# XMC4300 register map
Vendor: Infineon; File version: 0.5.1 (Superset device XMC4800)
CPU: CM4 r2p0, little endian, MPU, FPU, 6 interrupt priority bits
Registers are 32-bit, read-write, reset 0x0 unless marked. A register's access mark holds for its fields unless they carry their own. Offsets are from the block's base; [hi:lo] are bit positions; {n}, {i} and the like mark numbered series; 'fields as' and 'values as' point back to an identical list.

## DAC — Digital to Analog Converter
Base 0x48018000
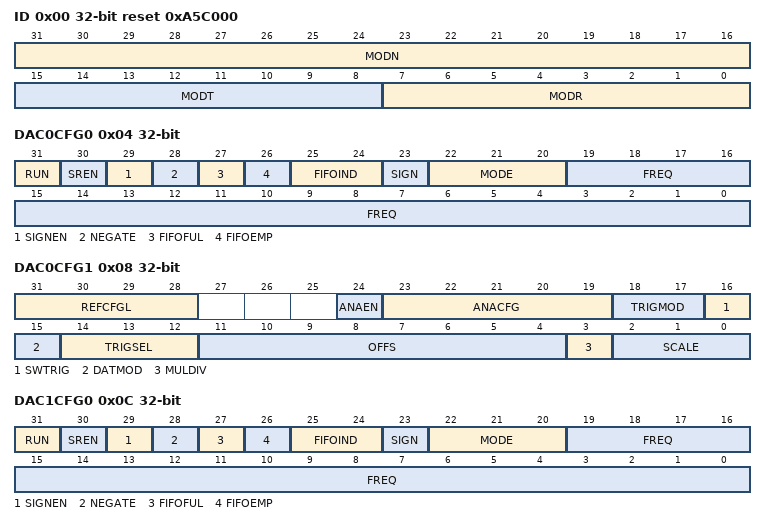
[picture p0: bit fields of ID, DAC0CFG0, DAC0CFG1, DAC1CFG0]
0x00 ID ro reset 0xA5C000 (reset mask 0xFFFFFF00) — Module Identification Register
  [31:16] MODN — Module Number
  [15:8] MODT — Module Type
  [7:0] MODR — Module Revision
0x04 DAC0CFG0 access per field — DAC0 Configuration Register 0
  [31] RUN ro — RUN indicates the current DAC0 operation status
    0=DAC0 channel disabled; 1=DAC0 channel in operation
  [30] SREN rw — Enable DAC0 service request interrupt generation
    0=disable; 1=enable
  [29] SIGNEN rw — Enable Sign Output of DAC0 Pattern Generator
    0=Disable; 1=Enable
  [28] NEGATE rw — Negates the DAC0 output
    0=DAC output not negated; 1=DAC output negated
  [27] FIFOFUL ro — Indicate if the FIFO is full
    0=FIFO not full; 1=FIFO full
  [26] FIFOEMP ro — Indicate if the FIFO is empty
    0=FIFO not empty; 1=FIFO empty
  [25:24] FIFOIND ro — Current write position inside the data FIFO
  [23] SIGN rw — Selects Between Signed and Unsigned DAC0 Mode
    0=DAC expects unsigned input data; 1=DAC expects signed input data
  [22:20] MODE rw — Enables and Sets the Mode for DAC0
    0=disable/switch-off DAC; 1=Single Value Mode; 2=Data Mode; 3=Patgen Mode; 4=Noise Mode; 5=Ramp Mode; 6=na; 7=na
  [19:0] FREQ rw — Integer Frequency Divider Value
0x08 DAC0CFG1 — DAC0 Configuration Register 1
  [31:28] REFCFGL — Lower 4 band-gap configuration/calibration parameters
  [24] ANAEN — Enable analog DAC for channel 0
    0=DAC0 is set to standby (analog output only); 1=enable DAC0 (analog output only)
  [23:19] ANACFG — DAC0 analog configuration/calibration parameters
  [18:17] TRIGMOD — Select the trigger source for channel 0
    0=internal Trigger (integer divided clock - see FREQ parameter); 1=external Trigger (preselected trigger by TRIGSEL parameter); 2=software Trigger (see SWTRIG parameter)
  [16] SWTRIG — Software Trigger
  [15] DATMOD — Switch between independent or simultaneous DAC mode and select the input data register for DAC0 and DAC1
    0=independent data handling - process data from DATA0 register (bits 11:0) to DAC0 and data from DATA1 register (bits 11:0) to DAC1; 1=simultaneous data handling - process data from DAC01 register to both DACs (bits 11:0 to DAC0 and bits 23:12 to DAC1)
  [14:12] TRIGSEL — Selects one of the eight external trigger sources for DAC0
  [11:4] OFFS — 8-bit offset value addition
  [3] MULDIV — Switch between up- and downscale of the DAC0 input data values
    0=downscale = division (shift SCALE positions to the right); 1=upscale = multiplication (shift SCALE positions to the left)
  [2:0] SCALE — Scale value for up- or downscale of the DAC0 input data in steps by the power of 2 (=shift operation)
    0=no shift = multiplication/division by 1; 1=shift by 1 = multiplication/division by 2; 2=shift by 2 = multiplication/division by 4; 3=shift left by 3 = multiplication/division by 8; 4=shift left by 4 = multiplication/division by 16; 5=shift left by 5 = multiplication/division by 32; 6=shift left by 6 = multiplication/division by 64; 7=shift left by 7 = multiplication/division by 128
0x0C DAC1CFG0 access per field — DAC1 Configuration Register 0
  [31] RUN ro — RUN indicates the current DAC1 operation status
    0=DAC1 channel disabled; 1=DAC1 channel in operation
  [30] SREN rw — Enable DAC1 service request interrupt generation
    0=disable; 1=enable
  [29] SIGNEN rw — Enable sign output of DAC1 pattern generator
    0=disable; 1=enable
  [28] NEGATE rw — Negates the DAC1 output
    0=DAC output not negated; 1=DAC output negated
  [27] FIFOFUL ro — Indicate if the FIFO is full
    0=FIFO not full; 1=FIFO full
  [26] FIFOEMP ro — Indicate if the FIFO is empty
    0=FIFO not empty; 1=FIFO empty
  [25:24] FIFOIND ro — Current write position inside the data FIFO
  [23] SIGN rw — Selects between signed and unsigned DAC1 mode
    values as DAC0CFG0.SIGN
  [22:20] MODE rw — Enables and sets the Mode for DAC1
    values as DAC0CFG0.MODE
  [19:0] FREQ rw — Integer Frequency Divider Value
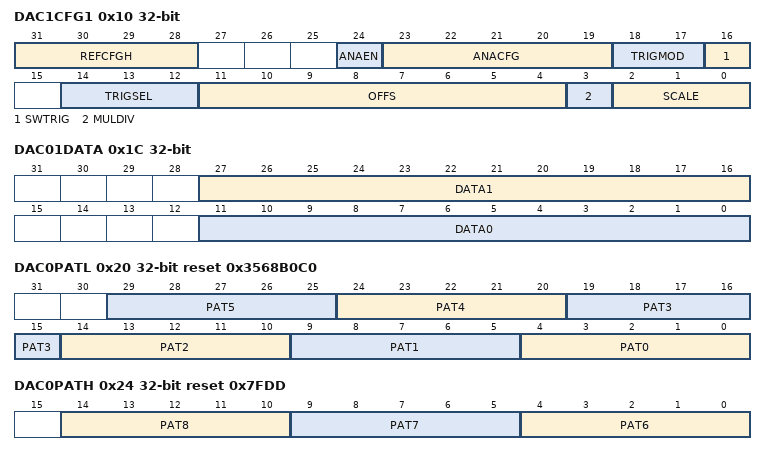
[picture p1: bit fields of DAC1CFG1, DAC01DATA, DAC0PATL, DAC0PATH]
0x10 DAC1CFG1 — DAC1 Configuration Register 1
  [31:28] REFCFGH — Higher 4 band-gap configuration/calibration parameters
  [24] ANAEN — Enable analog DAC for channel 1
    0=DAC1 is set to standby (analog output only); 1=enable DAC1 (analog output only)
  [23:19] ANACFG — DAC1 analog configuration/calibration parameters
  [18:17] TRIGMOD — Select the trigger source for channel 1
    values as DAC0CFG1.TRIGMOD
  [16] SWTRIG — Software Trigger
  [14:12] TRIGSEL — Selects one of the eight external trigger sources for DAC1
  [11:4] OFFS — 8-bit offset value addition
  [3] MULDIV — Switch between up- and downscale of the DAC1 input data values
    values as DAC0CFG1.MULDIV
  [2:0] SCALE — Scale value for up- or downscale of the DAC1 input data in steps by the power of 2 (=shift operation)
    values as DAC0CFG1.SCALE
0x14 DAC0DATA
  [11:0] DATA0 — DAC0 Data Bits
0x18 DAC1DATA
  [11:0] DATA1 — DAC1 Data Bits
0x1C DAC01DATA
  [27:16] DATA1 — DAC1 Data Bits
  [11:0] DATA0 — DAC0 Data Bits
0x20 DAC0PATL reset 0x3568B0C0 — DAC0 Lower Pattern Register
  [5n+4:5n] PAT{n} (n=0..5) — Pattern Number {n} for PATGEN of DAC0
0x24 DAC0PATH reset 0x7FDD — DAC0 Higher Pattern Register
  [14:10] PAT8 — Pattern Number 8 for PATGEN of DAC0
  [9:5] PAT7 — Pattern Number 7 for PATGEN of DAC0
  [4:0] PAT6 — Pattern Number 6 for PATGEN of DAC0
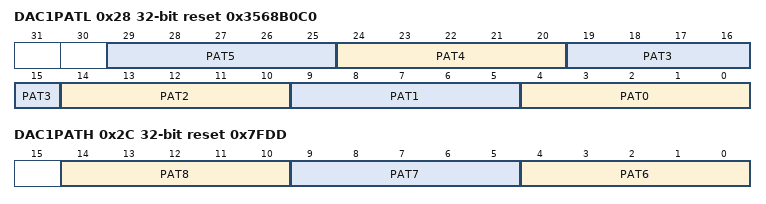
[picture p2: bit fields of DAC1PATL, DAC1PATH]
0x28 DAC1PATL reset 0x3568B0C0 — DAC1 Lower Pattern Register
  [5n+4:5n] PAT{n} (n=0..5) — Pattern Number {n} for PATGEN of DAC1
0x2C DAC1PATH reset 0x7FDD — DAC1 Higher Pattern Register
  [14:10] PAT8 — Pattern Number 8 for PATGEN of DAC1
  [9:5] PAT7 — Pattern Number 7 for PATGEN of DAC1
  [4:0] PAT6 — Pattern Number 6 for PATGEN of DAC1
